# STM32H7A3ZIT6Q register map
File version: 1.0
Registers are 32-bit, access not given, reset 0x0 unless marked. A register's access mark holds for its fields unless they carry their own. Offsets are from the block's base; [hi:lo] are bit positions; {n}, {i} and the like mark numbered series; 'fields as' and 'values as' point back to an identical list.

## FDCAN_CCU
Base 0x4000A800
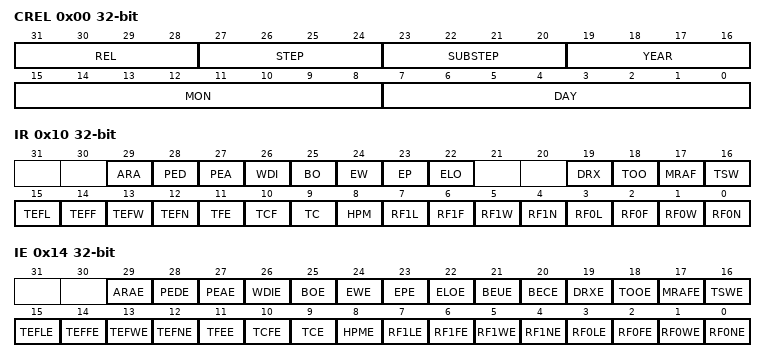
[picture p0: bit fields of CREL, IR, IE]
0x00 CREL
  [31:28] REL, [27:24] STEP, [23:20] SUBSTEP, [19:16] YEAR, [15:8] MON, [7:0] DAY
0x04 CCFG
0x08 CSTAT
0x0C CWD
0x10 IR
  [29] ARA, [28] PED, [27] PEA, [26] WDI, [25] BO, [24] EW, [23] EP, [22] ELO, [19] DRX, [18] TOO, [17] MRAF, [16] TSW, [15] TEFL, [14] TEFF, [13] TEFW, [12] TEFN, [11] TFE, [10] TCF, [9] TC, [8] HPM, [7] RF1L, [6] RF1F, [5] RF1W, [4] RF1N, [3] RF0L, [2] RF0F, [1] RF0W, [0] RF0N
0x14 IE
  [29] ARAE, [28] PEDE, [27] PEAE, [26] WDIE, [25] BOE, [24] EWE, [23] EPE, [22] ELOE, [21] BEUE, [20] BECE, [19] DRXE, [18] TOOE, [17] MRAFE, [16] TSWE, [15] TEFLE, [14] TEFFE, [13] TEFWE, [12] TEFNE, [11] TFEE, [10] TCFE, [9] TCE, [8] HPME, [7] RF1LE, [6] RF1FE, [5] RF1WE, [4] RF1NE, [3] RF0LE, [2] RF0FE, [1] RF0WE, [0] RF0NE

## SAI1
Base 0x40015800
Same registers: SAI2 0x40015C00
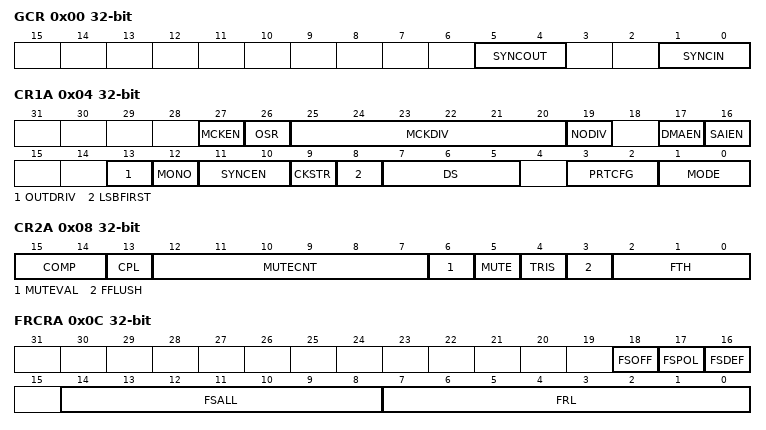
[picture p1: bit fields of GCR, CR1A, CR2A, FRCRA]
0x00 GCR
  [5:4] SYNCOUT, [1:0] SYNCIN
0x04 CR1A
  [27] MCKEN, [26] OSR, [25:20] MCKDIV, [19] NODIV, [17] DMAEN, [16] SAIEN, [13] OUTDRIV, [12] MONO, [11:10] SYNCEN, [9] CKSTR, [8] LSBFIRST, [7:5] DS, [3:2] PRTCFG, [1:0] MODE
0x08 CR2A
  [15:14] COMP, [13] CPL, [12:7] MUTECNT, [6] MUTEVAL, [5] MUTE, [4] TRIS, [3] FFLUSH, [2:0] FTH
0x0C FRCRA
  [18] FSOFF, [17] FSPOL, [16] FSDEF, [14:8] FSALL, [7:0] FRL
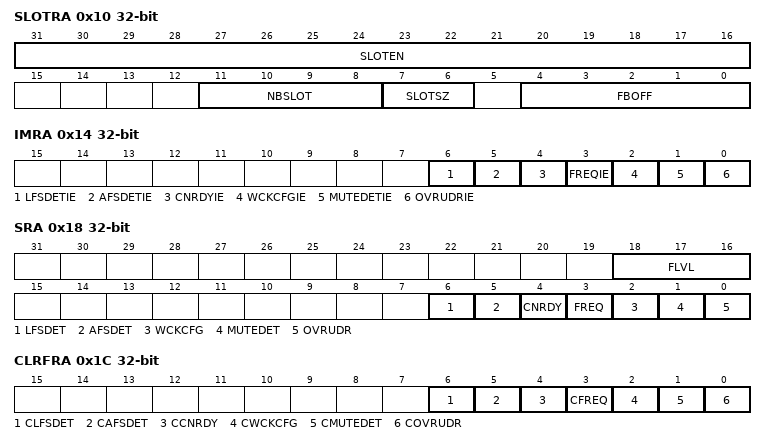
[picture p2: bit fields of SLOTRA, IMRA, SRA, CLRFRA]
0x10 SLOTRA
  [31:16] SLOTEN, [11:8] NBSLOT, [7:6] SLOTSZ, [4:0] FBOFF
0x14 IMRA
  [6] LFSDETIE, [5] AFSDETIE, [4] CNRDYIE, [3] FREQIE, [2] WCKCFGIE, [1] MUTEDETIE, [0] OVRUDRIE
0x18 SRA
  [18:16] FLVL, [6] LFSDET, [5] AFSDET, [4] CNRDY, [3] FREQ, [2] WCKCFG, [1] MUTEDET, [0] OVRUDR
0x1C CLRFRA
  [6] CLFSDET, [5] CAFSDET, [4] CCNRDY, [3] CFREQ, [2] CWCKCFG, [1] CMUTEDET, [0] COVRUDR
0x20 DRA
  [31:0] DATA
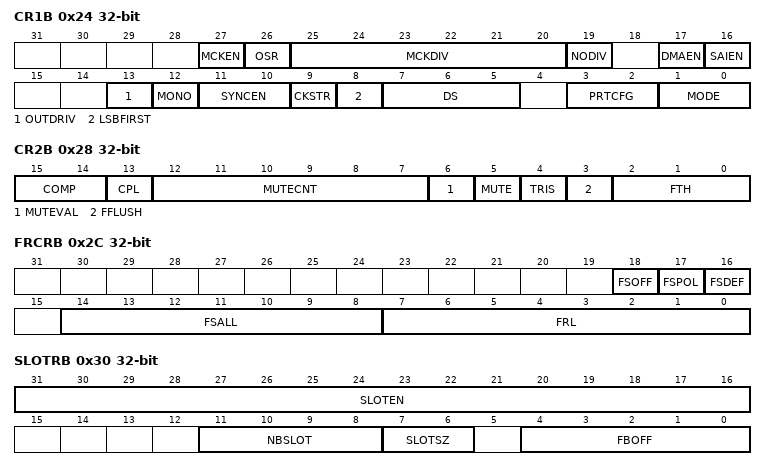
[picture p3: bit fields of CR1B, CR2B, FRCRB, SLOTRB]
0x24 CR1B
  fields as CR1A
0x28 CR2B
  fields as CR2A
0x2C FRCRB
  [18] FSOFF, [17] FSPOL, [16] FSDEF, [14:8] FSALL, [7:0] FRL
0x30 SLOTRB
  [31:16] SLOTEN, [11:8] NBSLOT, [7:6] SLOTSZ, [4:0] FBOFF
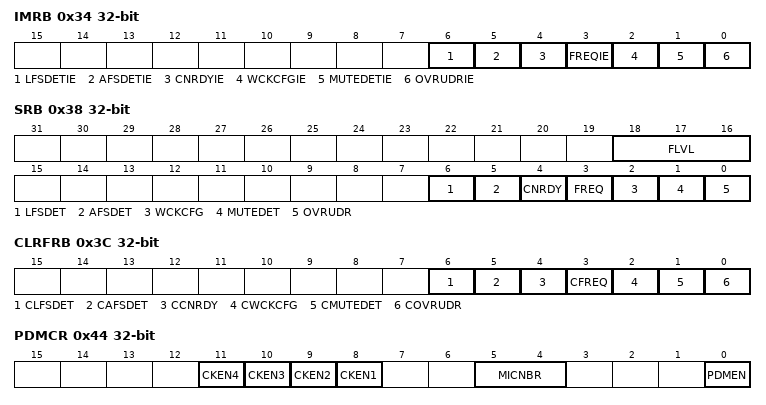
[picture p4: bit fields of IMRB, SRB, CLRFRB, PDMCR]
0x34 IMRB
  fields as IMRA
0x38 SRB
  fields as SRA
0x3C CLRFRB
  fields as CLRFRA
0x40 DRB
  [31:0] DATA
0x44 PDMCR
  [n+7] CKEN{n} (n=1..4), [5:4] MICNBR, [0] PDMEN
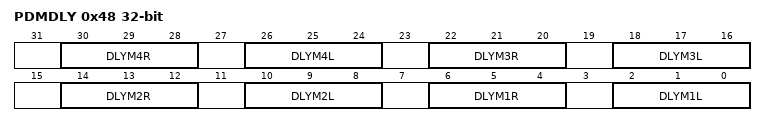
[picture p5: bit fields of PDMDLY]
0x48 PDMDLY
  [8n-2:8n-4] DLYM{n}R (n=1..4), [8n-6:8n-8] DLYM{n}L (n=1..4)

## DMA1
Base 0x40020000
Same registers: DMA2 0x40020400
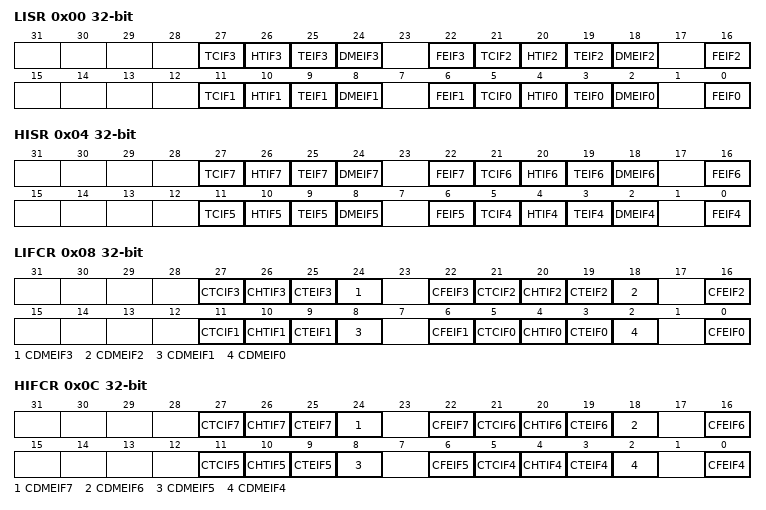
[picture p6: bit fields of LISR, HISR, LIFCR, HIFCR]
0x00 LISR
  [27] TCIF3, [26] HTIF3, [25] TEIF3, [24] DMEIF3, [22] FEIF3, [21] TCIF2, [20] HTIF2, [19] TEIF2, [18] DMEIF2, [16] FEIF2, [11] TCIF1, [10] HTIF1, [9] TEIF1, [8] DMEIF1, [6] FEIF1, [5] TCIF0, [4] HTIF0, [3] TEIF0, [2] DMEIF0, [0] FEIF0
0x04 HISR
  [27] TCIF7, [26] HTIF7, [25] TEIF7, [24] DMEIF7, [22] FEIF7, [21] TCIF6, [20] HTIF6, [19] TEIF6, [18] DMEIF6, [16] FEIF6, [11] TCIF5, [10] HTIF5, [9] TEIF5, [8] DMEIF5, [6] FEIF5, [5] TCIF4, [4] HTIF4, [3] TEIF4, [2] DMEIF4, [0] FEIF4
0x08 LIFCR
  [27] CTCIF3, [26] CHTIF3, [25] CTEIF3, [24] CDMEIF3, [22] CFEIF3, [21] CTCIF2, [20] CHTIF2, [19] CTEIF2, [18] CDMEIF2, [16] CFEIF2, [11] CTCIF1, [10] CHTIF1, [9] CTEIF1, [8] CDMEIF1, [6] CFEIF1, [5] CTCIF0, [4] CHTIF0, [3] CTEIF0, [2] CDMEIF0, [0] CFEIF0
0x0C HIFCR
  [27] CTCIF7, [26] CHTIF7, [25] CTEIF7, [24] CDMEIF7, [22] CFEIF7, [21] CTCIF6, [20] CHTIF6, [19] CTEIF6, [18] CDMEIF6, [16] CFEIF6, [11] CTCIF5, [10] CHTIF5, [9] CTEIF5, [8] CDMEIF5, [6] CFEIF5, [5] CTCIF4, [4] CHTIF4, [3] CTEIF4, [2] CDMEIF4, [0] CFEIF4
{0x10+0x18*i} CR{i} (i=0..7)
{0x14+0x18*i} NDTR{i} (i=0..7)
{0x18+0x18*i} PAR{i} (i=0..7)
{0x1C+0x18*i} M0AR{i} (i=0..7)
{0x20+0x18*i} M1AR{i} (i=0..7)
{0x24+0x18*i} FCR{i} (i=0..7)

## DMAMUX1
Base 0x40020800
Same registers: DMAMUX2 0x58025800
0x00 CCR0
0x04 CCR1
0x08 CCR2
0x0C CCR3
0x10 CCR4
0x14 CCR5
0x18 CCR6
0x1C CCR7
0x20 CCR8
0x24 CCR9
0x28 CCR0
0x2C CCR1
0x30 CCR2
0x34 CCR3
0x38 CCR4
0x3C CCR5
0x80 CCRs
0x100 CCR0
0x104 CCR1
0x108 CCR2
0x10C CCR3
0x110 CCR4
0x114 CCR5
0x118 CCR6
0x11C CCR7
0x140 CCRs
